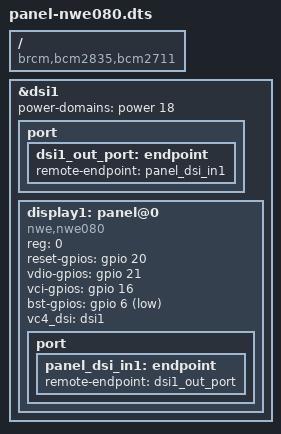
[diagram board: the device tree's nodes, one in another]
/dts-v1/;
/plugin/;

/ {
    compatible = "brcm,bcm2835,bcm2711";
                    
    fragment@1 {
        target=<&dsi1>;

        __overlay__ {
            status = "okay";

            power-domains = <&power 18>;

            #address-cells = <1>;
            #size-cells = <0>;

            port {
                dsi1_out_port: endpoint {
                    remote-endpoint = <&panel_dsi_in1>;
                };
            };


            display1: panel@0 {
                compatible = "nwe,nwe080";
                reg=<0>;

                reset-gpios = <&gpio 20 0>;
                vdio-gpios = <&gpio 21 0>;
                vci-gpios = <&gpio 16 0>;
                bst-gpios = <&gpio 6 1>;

                vc4_dsi = <&dsi1>;
                port {
                    panel_dsi_in1: endpoint {
                        remote-endpoint = <&dsi1_out_port>;
                    };
                };
            };
        };
    };
};
